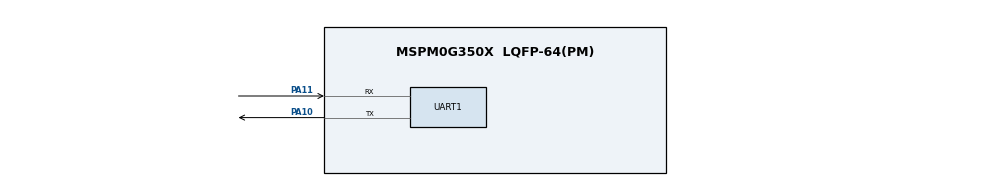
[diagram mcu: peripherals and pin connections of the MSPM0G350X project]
// @cliArgs --device "MSPM0G350X" --package "LQFP-64(PM)" --part "Default"
// @cliArgs --board /ti/boards/LP_MSPM0G3507 --rtos nortos

/**
 * Import the modules used in this configuration.
 */
const UART   = scripting.addModule("/ti/driverlib/UART", {}, false);
const UART1  = UART.addInstance();
const SYSCTL = scripting.addModule("/ti/driverlib/SYSCTL");

/**
 * Write custom configuration values to the imported modules.
 */

UART1.$name = "UART_0";
UART1.profile = "CONFIG_PROFILE_1";
UART1.peripheral.$assign = "UART0";
UART1.targetBaudRate = 9600;
UART1.enableInternalLoopback = false;
UART1.enabledInterrupts = ["RX"];
UART1.enableFIFO= false;

UART1.peripheral.rxPin.$assign = "PA11";
UART1.peripheral.txPin.$assign = "PA10";

SYSCTL.forceDefaultClkConfig = true;
SYSCTL.clockTreeEn  = true;
